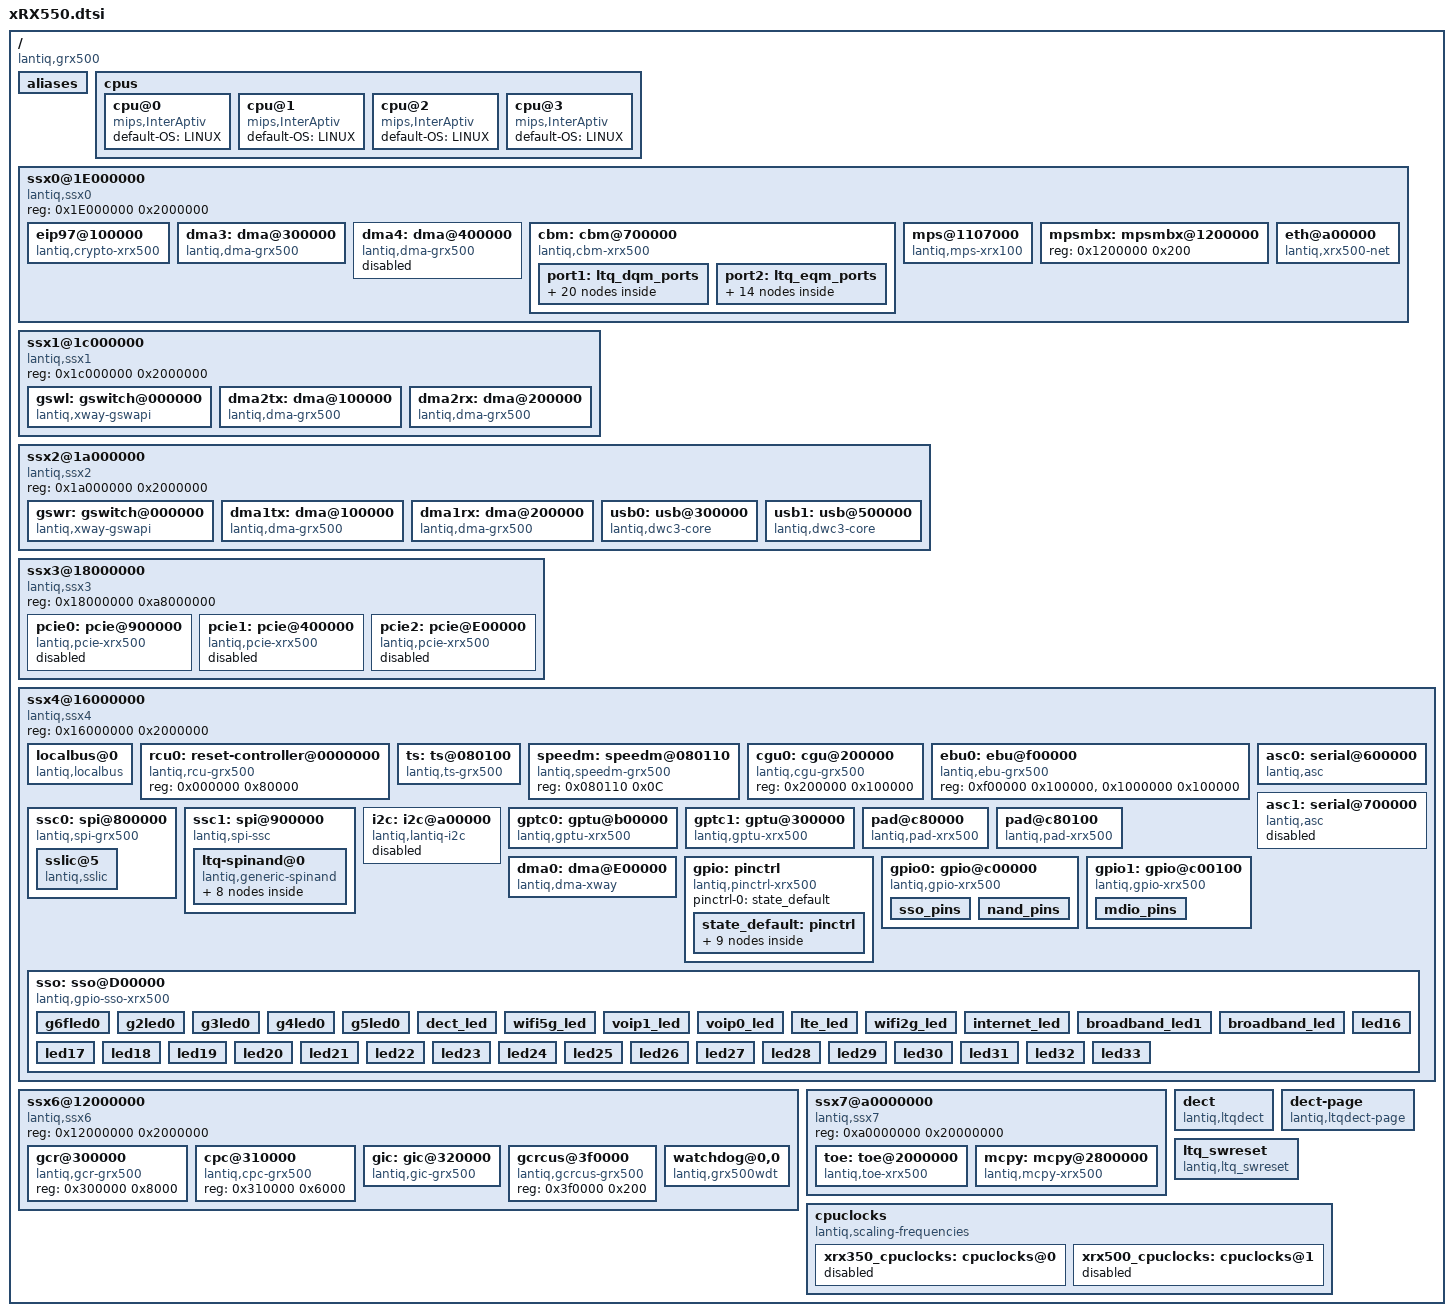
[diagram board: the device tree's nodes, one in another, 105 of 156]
/ {
	#address-cells = <1>;
	#size-cells = <1>;
	compatible = "lantiq,grx500","lantiq,xway";
	
	aliases {
		serial0 = &asc0;
		serial1 = &asc1;
		dma0    = &dma0;
		dma1    = &dma1tx;
		dma2    = &dma1rx;
		dma3    = &dma2tx;
		dma4    = &dma2rx;
		dma5    = &dma3;
		dma6    = &dma4;
		pcie0   = &pcie0;
		pcie1   = &pcie1;
		pcie2   = &pcie2;
		usb0	= &usb0;
		usb1	= &usb1;
		spi1 = &ssc1;
	};

	cpus {
		cpu@0 {
			compatible = "mips,InterAptiv";
			default-OS = "LINUX";
		};
		cpu@1 {
			compatible = "mips,InterAptiv";
			default-OS = "LINUX";
		};
		cpu@2 {
			compatible = "mips,InterAptiv";
			default-OS = "LINUX";
		};
		cpu@3 {
			compatible = "mips,InterAptiv";
			default-OS = "LINUX";
		};
	};

	ssx0@1E000000{
		#address-cells = <1>;
		#size-cells = <1>;
		compatible = "lantiq,ssx0", "simple-bus";
		reg = <0x1E000000 0x2000000>;
		ranges = <0x0 0x1E000000 0x02000000>;
		
		eip97@100000 {
			compatible = "lantiq,crypto-xrx500";
			reg = <0x100000 0x100000>;
			interrupt-parent = <&gic>;
			interrupts = <97 98 99>;
		};

		dma3: dma@300000 {
			compatible = "lantiq,dma-grx500";
			reg = <0x300000 0x100000>;
			interrupt-parent = <&gic>;
			interrupts = <77>;
			lantiq,dma-pkt-arb = <2>; /* 0 - burst, 1 - mulitburst, 2 - pkt */
			lantiq,dma-burst = <16>; /* 2, 4, 8, 16 */
			lantiq,dma-polling-cnt = <24>;
			lantiq,dma-chan-fc = <0>;
			lantiq,dma-desc-fod = <0>;
			lantiq,dma-desc-in-sram = <1>;
			lantiq,dma-drb = <0>;
			lantiq,dma-byte-en = <1>;
			lantiq,budget = <20>;
		};

		dma4: dma@400000 {
			status = "disabled";
			compatible = "lantiq,dma-grx500";
			reg = <0x400000 0x100000>;
			interrupt-parent = <&gic>;
			interrupts = <78>;
			lantiq,dma-pkt-arb = <2>; /* 0 - burst, 1 - mulitburst, 2 - pkt */
			lantiq,dma-burst = <16>; /* 2, 4, 8, 16 */
			lantiq,dma-polling-cnt = <24>;
			lantiq,dma-chan-fc = <0>;
			lantiq,dma-desc-fod = <0>;
			lantiq,dma-desc-in-sram = <0>;
			lantiq,dma-drb = <0>;

		};
		cbm: cbm@700000{
			compatible = "lantiq,cbm-xrx500";
			reg = < 0x700000 0x1000   /*TMU*/
				0x710000 0x10000 /*CBM*/
				0x720000 0x4000 /*QIDT*/
				0x730000 0x14000 /*SBIM*/
				0x750000 0x400 /*QEQCNTR*/
				0x750800 0x400 /*QDQCNTR*/
				0x760000 0x10000 /*LS*/
				0x780000 0x20000 /*CBM EQM*/
				0x7C0000 0x30000 /*CBM DQM*/
				0x800000 0x100000 /*FSQM0*/
				0x900000 0x100000 /*FSQM1*/
				0x500000 0x100000 /*CBM DMA DESC*/
				>;
				interrupt-parent = <&gic>;
				interrupts = <182 186 187 188 189>;
				/*<Port> <Queue> <DMA_Ctrl> <DMA_chnl> <EN/DIS/TYPE> <number of desc>*/
				/*<DIS 0>
				<EN 1>
				<TYPE DP_F_DEQ_CPU 0x2>
				<TYPE DP_F_DEQ_CPU1 0x3>
				<TYPE DP_F_DEQ_MPE 0x4>*/
				port1: ltq_dqm_ports {
					DQ6 {
						lantiq,cbm-config = <6 16 2 1 1 2>;
					};
					DQ7 {
						lantiq,cbm-config = <7 17 2 2 1 2>;
					};
					DQ8 {
						lantiq,cbm-config = <8 18 2 3 1 2>;
					};
					DQ9 {
						lantiq,cbm-config = <9 19 2 4 1 2>;
					};
					DQ10 {
						lantiq,cbm-config = <10 20 2 5 1 2>;
					};
					DQ11 {
						lantiq,cbm-config = <11 21 2 6 1 2>;
					};
					DQ12 {
						lantiq,cbm-config = <12 22 2 9 1 2>;
					};
					DQ13 {
						lantiq,cbm-config = <13 23 2 10 1 2>;
					};
					DQ14 {
						lantiq,cbm-config = <14 24 2 11 1 2>;
					};
					DQ15 {
						lantiq,cbm-config = <15 25 2 12 1 2>;
					};
					DQ16 {
						lantiq,cbm-config = <16 26 2 13 1 2>;
					};
					DQ17 {
						lantiq,cbm-config = <17 27 2 14 1 2>;
					};
					DQ19 {
						lantiq,cbm-config = <19 28 1 15 1 2>;
					};
					DQ20 {
						lantiq,cbm-config = <20 29 1 5 1 2>;
					};
					DQ21 {
						lantiq,cbm-config = <21 30 1 6 1 2>;
					};
					DQ18 {
						lantiq,cbm-config = <18 0 1 13 1 2>;
					};
					DQ23 {
						lantiq,cbm-config = <23 31 255 255 1 2>;
					};
					DQ4 {
						lantiq,cbm-config = <4 32 255 255 1 32>;
					};
					/*DQ0 {
						lantiq,cbm-config = <0 33 255 255 3 1>;
					};*/
					DQ2 {
						lantiq,cbm-config = <2 35 255 255 2 1>;
					};
					DQ5 {
						lantiq,cbm-config = <5 37 255 255 1 2>;
					};
				};
				/*<Port> <Queue> <DMA_Ctrl> <DMA_chnl> <EN/DIS/TYPE> <number of desc>*/
				/*<DIS 0>
				<EN 1>
				<TYPE DP_F_ENQ_CPU_0 0x2>
				<TYPE DP_F_ENQ_CPU_1 0x3>
				<TYPE DP_F_ENQ_CPU_2 0x4>
				<TYPE DP_F_ENQ_CPU_3 0x5>
				<TYPE DP_F_ENQ_WAVE  0x6>
				<TYPE DP_F_ENQ_GSWIPL 0x7>
				<TYPE DP_F_ENQ_PAE 0x8>
				<TYPE DP_F_ENQ_TSO 0x9>
				<TYPE DP_F_ENQ_VRX318 0xa>*/
			port2: ltq_eqm_ports {
					EQ1 {
						lantiq,cbm-config = <0 255 255 255 2 2>;
					};
					EQ2 {
						lantiq,cbm-config = <1 255 255 255 3 2>;
					};
					EQ3 {
						lantiq,cbm-config = <2 255 255 255 4 2>;
					};
					EQ4 {
						lantiq,cbm-config = <3 255 255 255 5 2>;
					};
					EQ5 {
						lantiq,cbm-config = <5 2 14 0 7 2>;
					};
					EQ5_1 {
						lantiq,cbm-config = <5 2 30 1 7 2>;
					};
					EQ6 {
						lantiq,cbm-config = <6 2 15 0 7 2>;
					};
					EQ6_1 {
						lantiq,cbm-config = <6 2 31 1 7 2>;
					};
					EQ7 {
						lantiq,cbm-config = <7 1 0 0 8 2>;
					};
					EQ7_1 {
						lantiq,cbm-config = <7 1 16 1 8 2>;
					};
					EQ8 {
						lantiq,cbm-config = <8 1 15 0 8 2>;
					};
					EQ8_1 {
						lantiq,cbm-config = <8 1 31 1 8 2>;
					};
					EQ9 {
						lantiq,cbm-config = <9 255 255 255 9 2>;
					};
					EQ15 {
						lantiq,cbm-config = <15 255 255 255 10 32>;
					};
			};
		};

		mps@1107000 {
			compatible = "lantiq,mps-xrx100";
			reg = <0x1107000 0x400>;
			interrupt-parent = <&gic>;
			interrupts = <154 155>;
			lantiq,mbx = <&mpsmbx>;
		};

		mpsmbx: mpsmbx@1200000 {
			reg = <0x1200000 0x200>;
		};

		eth@a00000{
			#address-cells = <1>;
			#size-cells = <0>;
			compatible = "lantiq,xrx500-net";
		};
	};

	ssx1@1c000000 {
		#address-cells = <1>;
		#size-cells = <1>;
		compatible = "lantiq,ssx1", "simple-bus";
		reg = <0x1c000000 0x2000000>;
		ranges = <0x0 0x1c000000 0x02000000>;

		gswl: gswitch@000000 {
			compatible = "lantiq,xway-gswapi";
			reg = <0x000000 0x3000>;
			lantiq,gsw-devid = <0>;
		};

		dma2tx: dma@100000 {
			compatible = "lantiq,dma-grx500";
			reg = <0x100000 0x100000>;
			interrupt-parent = <&gic>;
			interrupts = <75>;
			lantiq,dma-pkt-arb = <2>; /* 0 - burst, 1 - mulitburst, 2 - pkt */
			lantiq,dma-burst = <16>; /* 2, 4, 8, 16 */
			lantiq,dma-polling-cnt = <24>;
			lantiq,dma-chan-fc = <1>;
			lantiq,dma-desc-fod = <1>;
			lantiq,dma-desc-in-sram = <0>;
			lantiq,dma-drb = <0>;
			lantiq,dma-byte-en = <1>;
			lantiq,budget = <20>;
		};

		dma2rx: dma@200000 {
			compatible = "lantiq,dma-grx500";
			reg = <0x200000 0x100000>;
			interrupt-parent = <&gic>;
			interrupts = <76>;
			lantiq,dma-pkt-arb = <2>; /* 0 - burst, 1 - mulitburst, 2 - pkt */
			lantiq,dma-burst = <16>; /* 2, 4, 8, 16 */
			lantiq,dma-polling-cnt = <24>;
			lantiq,dma-chan-fc = <0>;
			lantiq,dma-desc-fod = <1>;
			lantiq,dma-desc-in-sram = <0>;
			lantiq,dma-drb = <0>;
			lantiq,dma-byte-en = <1>;
			lantiq,budget = <20>;
		};
	};

	ssx2@1a000000 {
		#address-cells = <1>;
		#size-cells = <1>;
		compatible = "lantiq,ssx2", "simple-bus";
		reg = <0x1a000000 0x2000000>;
		ranges = <0x0 0x1a000000 0x02000000>;

		gswr: gswitch@000000 {
			compatible = "lantiq,xway-gswapi";
			reg = <0x000000 0x3000>;
			lantiq,gsw-devid = <1>;
		};

		dma1tx: dma@100000 {
			compatible = "lantiq,dma-grx500";
			reg = <0x100000 0x100000>;
			interrupt-parent = <&gic>;
			interrupts = <73>;
			lantiq,dma-pkt-arb = <2>; /* 0 - burst, 1 - mulitburst, 2 - pkt */
			lantiq,dma-burst = <16>; /* 2, 4, 8, 16 */
			lantiq,dma-polling-cnt = <24>;
			lantiq,dma-chan-fc = <1>;
			lantiq,dma-desc-fod = <1>;
			lantiq,dma-desc-in-sram = <0>;
			lantiq,dma-drb = <0>;
			lantiq,dma-byte-en = <1>;
			lantiq,budget = <20>;
		};

		dma1rx: dma@200000 {
			compatible = "lantiq,dma-grx500";
			reg = <0x200000 0x100000>;
			interrupt-parent = <&gic>;
			interrupts = <74>;
			lantiq,dma-pkt-arb = <2>; /* 0 - burst, 1 - mulitburst, 2 - pkt */
			lantiq,dma-burst = <16>; /* 2, 4, 8, 16 */
			lantiq,dma-polling-cnt = <24>;
			lantiq,dma-chan-fc = <0>;
			lantiq,dma-desc-fod = <1>;
			lantiq,dma-desc-in-sram = <0>;
			lantiq,dma-drb = <0>;
			lantiq,dma-byte-en = <0>;
			lantiq,budget = <20>;
		};

		usb0:usb@300000 {
			compatible = "lantiq,dwc3-core";
			reg = <0x300000 0x100000>;
			interrupt-parent = <&gic>;
			interrupts = <62>;
			vbus-gpio = <&gpio0 7 0>;
		};

		usb1:usb@500000 {
			compatible = "lantiq,dwc3-core";
			reg = <0x500000 0x100000>;
			interrupt-parent = <&gic>;
			interrupts = <91>;
			vbus-gpio = <&gpio0 2 0>;
		};
	};

	ssx3@18000000 {
		#address-cells = <1>;
		#size-cells = <1>;
		compatible = "lantiq,ssx3", "simple-bus";
		reg = <0x18000000 0xa8000000>;
		ranges = <0x0 0x18000000 0xa8000000>;

		pcie0:pcie@900000 {
			status = "disabled";
			compatible = "lantiq,pcie-xrx500";
			device_type = "pci";
			#address-cells = <3>;
			#size-cells = <2>;
			reg = < 
				0x900000 0x100000 /* RC controller */
				0xA3000000 0x800000 /* Cfg*/
				0x800000 0x100000 /* App logic */
				0x500000 0x100000 /* PCIe PHY Reg */
				0x600000 0x100000 /* MSI addr space */
				0x700000 0x100000 /* MSI PIC */
			>;
			reg-names = "csr", "cfg", "app", "phy", "msi", "pic";
			interrupt-parent = <&gic>;
			interrupts = <136 137 138 139 140 141 142 143 160>;
			interrupt-names = "msi0", "msi1", "msi2", "msi3", "msi4", "msi5", "msi6", "msi7", "ir";
			#interrupt-cells = <1>;
			interrupt-map-mask = <0 0 0 0x7>;
			interrupt-map = <0 0 0 1 &gic  144>,
					<0 0 0 2 &gic  145>,
					<0 0 0 3 &gic  146>,
					<0 0 0 4 &gic  147>;
			ranges = <0x02000000 0 0xa0000000 0xa0000000 0 0x03000000    /* Non-pretechable memory 32bit */
				  0x01000000 0 0xa3800000 0xa3800000 0 0x00100000    /* Downsream I/O */ 
				 >;

			resets = <&rcu0 12>; 
			reset-names = "phy";
			lantiq,inbound-shift = <5>;
			lantiq,outbound-shift = <4>;
			lantiq,clkout = <22>;
		};

		pcie1:pcie@400000 {
			status = "disabled";
			compatible = "lantiq,pcie-xrx500";
			device_type = "pci";
			#address-cells = <3>;
			#size-cells = <2>;
			reg = <
				0x400000 0x100000 /* RC controller */
				0x9f000000 0x800000 /* Cfg*/
				0x300000 0x100000 /* App logic */
				0x000000 0x100000 /* PCIe PHY Reg */
				0x100000 0x100000 /* MSI phy space */
				0x200000 0x100000 /* MSI PIC */
				
			>;
			reg-names = "csr", "cfg", "app", "phy", "msi", "pic";
			interrupt-parent = <&gic>;
			interrupts = <45 46 47 48 49 50 51 52 57>;
			interrupt-names = "msi0", "msi1", "msi2", "msi3", "msi4", "msi5", "msi6", "msi7", "ir";
			#interrupt-cells = <1>;
			interrupt-map-mask = <0 0 0 0x7>;
			interrupt-map = <0 0 0 1 &gic  17>,
					<0 0 0 2 &gic  18>,
					<0 0 0 3 &gic  19>,
					<0 0 0 4 &gic  20>;
			ranges = < 0x02000000 0 0x9c000000 0x9c000000 0 0x03000000    /* Non-pretechable memory 32bit */
				   0x01000000 0 0x9f800000 0x9f800000 0 0x00100000    /* Downsream I/O */ 
				 >;
						
			resets = <&rcu0 13>; 
			reset-names = "phy";
			lantiq,inbound-shift = <9>;
			lantiq,outbound-shift = <8>;
			lantiq,clkout = <23>;
		};

		pcie2:pcie@E00000 {
			status = "disabled";
			compatible = "lantiq,pcie-xrx500";
			#address-cells = <3>;
			#size-cells = <2>;
			device_type = "pci";
			reg = <
				0xe00000 0x100000 /* RC controller */
				0xa7000000 0x800000 /* Cfg*/
				0xd00000 0x100000 /* App logic */
				0xa00000 0x100000 /* PCIe PHY Reg */
				0xb00000 0x100000 /* MSI addr space */
				0xc00000 0x100000 /* MSI PIC */
			>;
			reg-names = "csr", "cfg", "app", "phy", "msi", "pic";
			interrupt-parent = <&gic>;
			interrupts = <32 33 34 35 36 37 38 39 63>;
			interrupt-names = "msi0", "msi1", "msi2", "msi3", "msi4", "msi5", "msi6", "msi7", "ir";
			#interrupt-cells = <1>;
			interrupt-map-mask = <0 0 0 0x7>;
			interrupt-map = <0 0 0 1 &gic  163>,
					<0 0 0 2 &gic  164>,
					<0 0 0 3 &gic  165>,
					<0 0 0 4 &gic  166>;
			ranges = < 0x02000000 0 0xa4000000 0xa4000000 0 0x03000000    /* Non-pretechable memory 32bit */
				   0x01000000 0 0xa7800000 0xa7800000 0 0x00100000    /* Downsream I/O */ 
				 >;
			resets = <&rcu0 10>; 
			reset-names = "phy";
			lantiq,inbound-shift = <13>;
			lantiq,outbound-shift = <12>;
			lantiq,clkout = <24>;
		};
	};

	ssx4@16000000 {
		#address-cells = <1>;
		#size-cells = <1>;
		compatible = "lantiq,ssx4", "simple-bus";
		reg = <0x16000000 0x2000000>;
		ranges = <0x0 0x16000000 0x02000000>;

		localbus@0 {
			#address-cells = <2>;
			#size-cells = <1>;
			ranges = <0 0 0x1400000 0xc00000 /* addrsel0 */
			1 0 0x1c00000 0x100000>; /* addsel1 */
			compatible = "lantiq,localbus", "simple-bus";
		};

		rcu0: reset-controller@0000000 {
			compatible = "lantiq,rcu-grx500";
			reg = <0x000000 0x80000>;
			#reset-cells = <1>; 
		};

		ts: ts@080100 {
			compatible = "lantiq,ts-grx500" , "lantiq,ts-xrx500"; 
			reg = <0x080100 0x0C>;
			interrupt-parent = <&gic>;
			interrupts = <27>;
			lantiq,numofsensors = <0x2>;
		}; 

		speedm: speedm@080110 {
			compatible = "lantiq,speedm-grx500" , "lantiq,speedm-xrx500"; 
			reg = <0x080110 0x0C>;
		}; 

		cgu0: cgu@200000 {
			compatible = "lantiq,cgu-grx500";
			reg = <0x200000 0x100000>;
		};

		ebu0: ebu@f00000 {
			compatible = "lantiq,ebu-grx500";
			reg = <0xf00000 0x100000>,
				<0x1000000 0x100000>; 
			reg-names = "ebunand_reg", "hsnand_reg";
		};

		asc0: serial@600000 {
			compatible = "lantiq,asc";
			reg = <0x600000 0x100000>;
			interrupt-parent = <&gic>;
			interrupts = <111 113 114>;
		};

		asc1: serial@700000 {
			compatible = "lantiq,asc";
			reg = <0x700000 0x100000>;
			interrupt-parent = <&gic>;
			interrupts = <84 86 87>;
			status = "disabled";
		};

		ssc0: spi@800000 {
			compatible = "lantiq,spi-grx500";
			reg = <0x800000 0x400>;
			interrupt-parent = <&gic>;
			interrupts = <22 23 24>;
			#address-cells = <1>;
			#size-cells = <0>;

			sslic@5 {
				compatible = "lantiq,sslic";
				spi-max-frequency = <8000000>;
				reg = <5>;
				interrupts = <217>;
				interrupt-parent = <&gic>;
			};
		};

		ssc1: spi@900000 {
			compatible = "lantiq,spi-ssc";
			reg = <0x900000 0x400>;
			interrupt-parent = <&gic>;
			interrupts = <107 108 109>;
			#address-cells = <1>;
			#size-cells = <1>;
			lantiq,ssc-port = <1>;
			ltq-spinand@0 {
				#address-cells = <1>;
				#size-cells = <1>;
				reg = <0 1>;
				compatible = "lantiq,generic-spinand";
				linux,mtd-name = "17c00000.nand-parts";
				spi-max-frequency = <1000000>;

				partition@0 {
						label = "uboot";
						reg = <0x000000 0x100000>;
				};

				partition@100000 {
						label = "ubootconfigA";
						reg = <0x100000 0x40000>;
				};

				partition@140000 {
						label = "ubootconfigB";
						reg = <0x140000 0x40000>;
				};

				partition@180000 {
						label = "gphyfirmware";
						reg = <0x180000 0x40000>;
				};

				partition@1c0000 {
						label = "calibration";
						reg = <0x1c0000 0x100000>;
				};

				partition@2c0000 {
						label = "Bootcore";
						reg = <0x2c0000 0x1000000>;
				};

				partition@12c0000 {
						label = "system_sw";
						reg = <0x12c0000 0x6C00000>;
				};

				partition@7Ec0000 {
						label = "res";
						reg = <0x7EC0000 0x140000>;
				};
			};
		};

		i2c: i2c@a00000 {
			#address-cells = <1>;
			#size-cells = <0>;
			status = "disabled";
			compatible = "lantiq,lantiq-i2c";
			reg = <0xa00000 0x10000>;
			interrupt-parent = <&gic>;
			interrupts = <41 40 31 44>;
			clock-frequency = <100000>;
		};

		gptc0: gptu@b00000 {
			compatible = "lantiq,gptu-xrx500";
			reg = <0xb00000 0x400>;
			interrupt-parent = <&gic>;
			interrupts = <126 127 128 129 130 131>;
		};

		gptc1: gptu@300000 {
			compatible = "lantiq,gptu-xrx500";
			reg = <0x300000 0x400>;
			interrupt-parent = <&gic>;
			interrupts = <168 169 170 171 172 173>;
		};

		pad@c80000{
			compatible = "lantiq,pad-xrx500";
			lantiq,bank = <0>;
			reg = <0xc80000 0x100>;
		};

		pad@c80100{
			compatible = "lantiq,pad-xrx500";
			lantiq,bank = <1>;
			reg = <0xc80100 0x100>;
			lantiq,bbspi-en = <0>;
		};

		dma0: dma@E00000 {
			compatible = "lantiq,dma-xway","lantiq,dma0-grx500";
			reg = <0xE00000 0x100000>;
			interrupt-parent = <&gic>;
			interrupts = <72>;
			lantiq,desc-num = <16>;
			lantiq,dma-burst = <2>;
			lantiq,dma-polling-cnt = <4>;
			lantiq,dma-drb = <1>;
			lantiq,budget = <20>;
		};

		gpio: pinctrl {
			compatible = "lantiq,pinctrl-xrx500";
			pinctrl-names = "default";
			pinctrl-0 = <&state_default>;


			state_default: pinctrl {
				ledc {
					lantiq,groups = "ledc";
					lantiq,function = "ledc";
				};
				i2c {
					lantiq,groups = "i2c";
					lantiq,function = "i2c";
				};
				spi0 {
					lantiq,groups = "spi0", "spi0_cs1";
					lantiq,function = "spi0";
				};
				spi1 {
					lantiq,groups = "spi1", "spi1_cs0";
					lantiq,function = "spi1";
				};

				nand {
					lantiq,groups = "nand cle", "nand ale", 
						"nand rd", "nand rdy",
						"nand d0", "nand d1",
						"nand d2", "nand d3",
						"nand d4", "nand d5",
						"nand d6", "nand d7",
						"nand cs1", "nand wr",
						"nand wp", "nand se";
					lantiq,function = "ebu";   
				};

				mdio {
					lantiq,groups = "mdio_l", "mdio_r";
					lantiq,function = "mdio";
				};

				vcodec {
					lantiq,groups = "vcodec", "clkout0";
					lantiq,function = "vcodec";
				};
				
				conf {
					lantiq,pins = "io32", "io33", "io42", "io43";
					lantiq,open-drain = <1>;
				};
				
				conf_pull {
					lantiq,pins = "io35";
					lantiq,pull = <0>;
				};
			};
		};

		gpio0: gpio@c00000 {
			compatible = "lantiq,gpio-xrx500";
			gpio-controller;
			#gpio-cells = <2>;
			reg = <0xc00000 0x80>;
			interrupt-parent = <&gic>;
			interrupts = <180>;
			lantiq,bank = <0>;
			sso_pins: sso_pins {
				hog-as-output;
				gpio = <4 5 6>;
			};
			nand_pins: nand_pins {
				hog-as-output;
				gpio = <24 13 49 50 51 52 53 54 55 56 57 23 59 60 61>;
			};
		};

		gpio1: gpio@c00100 {
			compatible = "lantiq,gpio-xrx500";
			gpio-controller;
			#gpio-cells = <2>;
			reg = <0xc00100 0x80>;
			interrupt-parent = <&gic>;
			interrupts = <181>;
			lantiq,bank = <1>;
			mdio_pins: mdio_pins {
				hog-as-output;
				gpio = <32 33 42 43>;
			};
		};

		sso: sso@D00000 {
			compatible = "lantiq,gpio-sso-xrx500";
			reg = <0xD00000 0x2CC>;
			#gpio-cells = <2>;
			gpio-controller;

			lantiq,groups = <0x3>;
			lantiq,phy2 = <0x1>;
			lantiq,phy3 = <0x1>;
			lantiq,phy4 = <0x1>;
			lantiq,phy5 = <0x1>;
			lantiq,phy6 = <0x1>;
			/* lantiq,rising; */
			#address-cells = <1>;
			#size-cells = <0>;
			g6fled0 {
				label = "g6fled0";
				reg = <0x0>;
			};
			g2led0 {
				label = "g2led0";
				reg = <0x1>;
			};
			g3led0 {
				label = "g3led0";
				reg = <0x2>;
			};
			g4led0 {
				label = "g4led0";
				reg = <0x3>;
			};
			g5led0 {
				label = "g5led0";
				reg = <0x4>;
			};
			dect_led {
				label = "dect_led";
				reg = <0x5>;
			};
			wifi5g_led {
				label = "wifi5g_led";
				reg = <0x6>;
			};
			voip1_led {
				label = "voip1_led";
				reg = <0x7>;
			};
			voip0_led {
				label = "voip0_led";
				reg = <0x8>;
			};
			lte_led {
				label = "lte_led";
				reg = <0x9>;
			};
			wifi2g_led {
				label = "wifi2g_led";
				reg = <0xa>;
			};
			internet_led {
				label = "internet_led";
				reg = <0xb>;
			};
			broadband_led1 {
				label = "broadband_led1";
				reg = <0xc>;
			};
			broadband_led {
				label = "broadband_led";
				reg = <0xd>;
			};
			led16 {
				label = "led16";
				reg = <0xe>;
			};
			led17 {
				label = "led17";
				reg = <0xf>;
			};
			led18 {
				label = "led18";
				reg = <0x10>;
			};
			led19 {
				label = "led19";
				reg = <0x11>;
			};
			led20 {
				label = "led20";
				reg = <0x12>;
			};
			led21 {
				label = "led21";
				reg = <0x13>;
			};
			led22 {
				label = "led22";
				reg = <0x14>;
			};
			led23 {
				label = "led23";
				reg = <0x15>;
			};
			led24 {
				label = "led24";
				reg = <0x16>;
			};
			led25 {
				label = "led25";
				reg = <0x17>;
			};
			led26 {
				label = "led26";
				reg = <0x18>;
			};
			led27 {
				label = "led27";
				reg = <0x19>;
			};
			led28 {
				label = "led28";
				reg = <0x1a>;
			};
			led29 {
				label = "led29";
				reg = <0x1b>;
			};
			led30 {
				label = "led30";
				reg = <0x1c>;
			};
			led31 {
				label = "led31";
				reg = <0x1d>;
			};
			led32 {
				label = "led32";
				reg = <0x1e>;
			};
			led33 {
				label = "led33";
				reg = <0x1f>;
			};
		};
	};

	ssx6@12000000 {
		#address-cells = <1>;
		#size-cells = <1>;
		compatible = "lantiq,ssx6", "simple-bus";
		reg = <0x12000000 0x2000000>;
		ranges = <0x0 0x12000000 0x02000000>;

		gcr@300000 {
			compatible = "lantiq,gcr-grx500";
			reg = <0x300000 0x8000>;
		};

		cpc@310000 {
			compatible = "lantiq,cpc-grx500";
			reg = <0x310000 0x6000>;
		};
	
		gic: gic@320000 {
			#interrupt-cells = <1>;
			interrupt-controller;
			compatible = "lantiq,gic-grx500";
			reg = <0x320000 0x20000>;
		};
		
		gcrcus@3f0000 {
			compatible = "lantiq,gcrcus-grx500";
			reg = <0x3f0000 0x200>;
		};

		watchdog@0,0 {
			#interrupt-cells = <1>;
			compatible = "lantiq,grx500wdt";
			reg = <0 0>;
			interrupt-parent = <&gic>;
			interrupts = <264>;
			timeout-sec = <5>;
		};
	};

	ssx7@a0000000 {
		#address-cells = <1>;
		#size-cells = <1>;
		compatible = "lantiq,ssx7", "simple-bus";
		reg = <0xa0000000 0x20000000>;
		ranges = <0x0 0xa0000000 0x20000000>;

		toe: toe@2000000 {
			#address-cells = <1>;
			#size-cells = <1>;
			compatible = "lantiq,toe-xrx500";
			reg = <0x2000000 0x800000>;
			interrupt-parent = <&gic>;
			interrupts = <79 80 81 82 83 190 191 192 193 194 195 196 197 198 199>;
		};

		mcpy: mcpy@2800000 {
			#address-cells = <1>;
			#size-cells = <1>;
			compatible = "lantiq,mcpy-xrx500";
			reg = <0x2800000 0x800000>;
			interrupt-parent = <&gic>;
			interrupts = <208 209 210 211 212 213 214 215 216>;
			lantiq,mcpy-yld = <200 201 202 203 204 205 206 207>;
			lantiq,mcpy-trnksz = <1>;
			lantiq,mcpy-irq-interval = <40>;
			lantiq,mcpy-prio = <1 0 1 0 1 0 1 0>; /* 1 is High prio */
			lantiq,mcpy-vpe  = <0 0 1 1 2 2 3 3>;
			lantiq,mcpy-ylden = <1 0 1 0 1 0 1 0>;
			lantiq,umt-period = <0x2000>;
		}; 
	};	
	
        dect {
                compatible = "lantiq,ltqdect";
                lantiq,dect-spi-int=<302>; /*271 GPIO base + GPIO 31 for cosic interrupt and driver Probe fn will look for string dect-spi-int */
                lantiq,dect-cs= <0>; /*DECT chip select port Number; This is used by SSC interface*/
                gpio-reset = <&gpio0 28 0>; /*COSIC Reset PIN connected to GPIO 28*/
                status = "okay";
        };

        dect-page {
                compatible = "lantiq,ltqdect-page";
                lantiq,pagepin= <&gpio0 29 0>; /*DECT Page Pin connected to GPIO 29*/
                lantiq,pagebit= <1>; /*DECT Page Bit: Bit info meant for DECT*/
                status = "okay";
        };

	ltq_swreset {
		compatible = "lantiq,ltq_swreset";
		swreset_pin = <&gpio0 0 0>;
		swreset_bit = <1>;
		status = "okay";
	};

	cpuclocks {
		compatible = "lantiq,scaling-frequencies";

		xrx350_cpuclocks: cpuclocks@0 {
			status = "disabled";
			lantiq,cpuclocks = <800000000 600000000 150000000 50000000>;
			lantiq,ddrclocks = <333000000 333000000 166000000 166000000>;
		}; 
	
		xrx500_cpuclocks: cpuclocks@1 {
			status = "disabled";
			lantiq,cpuclocks = <1200000000 800000000 150000000 50000000>;
			lantiq,ddrclocks = <400000000 333000000 166000000 166000000>;
		};
	}; 
};
